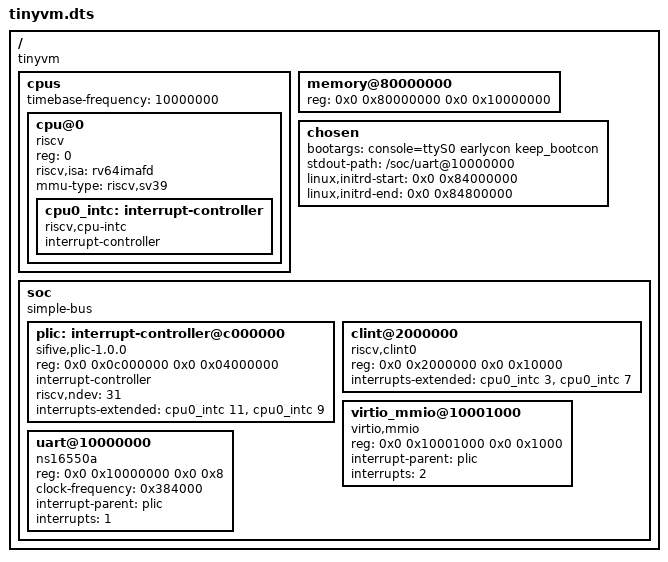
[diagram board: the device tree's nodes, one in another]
/dts-v1/;

/ {
	#address-cells = <2>;
	#size-cells = <2>;
	compatible = "tinyvm";

	cpus {
		#address-cells = <1>;
		#size-cells = <0>;
		timebase-frequency = <10000000>; // CLINT mtime ticks at 10MHz (1 tick per cpu step, ~10M steps/sec)

		cpu@0 {
			device_type = "cpu";
			compatible = "riscv";
			reg = <0>;
			riscv,isa = "rv64imafd";
			mmu-type = "riscv,sv39";

			cpu0_intc: interrupt-controller {
				compatible = "riscv,cpu-intc";
				interrupt-controller;
				#interrupt-cells = <1>;
			};
		};
	};

	memory@80000000 {
		device_type = "memory";
		reg = <0x0 0x80000000 0x0 0x10000000>; // 256MB at 0x80000000
	};

	chosen {
		bootargs = "console=ttyS0 earlycon keep_bootcon";
		stdout-path = "/soc/uart@10000000";
		linux,initrd-start = <0x0 0x84000000>;
		linux,initrd-end = <0x0 0x84800000>; // 8MB window — cpio parser stops at TRAILER marker
	};

	soc {
		#address-cells = <2>;
		#size-cells = <2>;
		compatible = "simple-bus";
		ranges;

		plic: interrupt-controller@c000000 {
			compatible = "sifive,plic-1.0.0", "riscv,plic0";
			reg = <0x0 0x0c000000 0x0 0x04000000>;
			interrupt-controller;
			#interrupt-cells = <1>;
			riscv,ndev = <31>;
			interrupts-extended = <&cpu0_intc 11 &cpu0_intc 9>;
		};

		clint@2000000 {
			compatible = "riscv,clint0";
			reg = <0x0 0x2000000 0x0 0x10000>;
			interrupts-extended = <&cpu0_intc 3 &cpu0_intc 7>;
		};

		virtio_mmio@10001000 {
			compatible = "virtio,mmio";
			reg = <0x0 0x10001000 0x0 0x1000>;
			interrupt-parent = <&plic>;
			interrupts = <2>;
		};

		uart@10000000 {
			compatible = "ns16550a";
			reg = <0x0 0x10000000 0x0 0x8>;
			clock-frequency = <0x384000>;
			interrupt-parent = <&plic>;
			interrupts = <1>;
		};
	};
};
